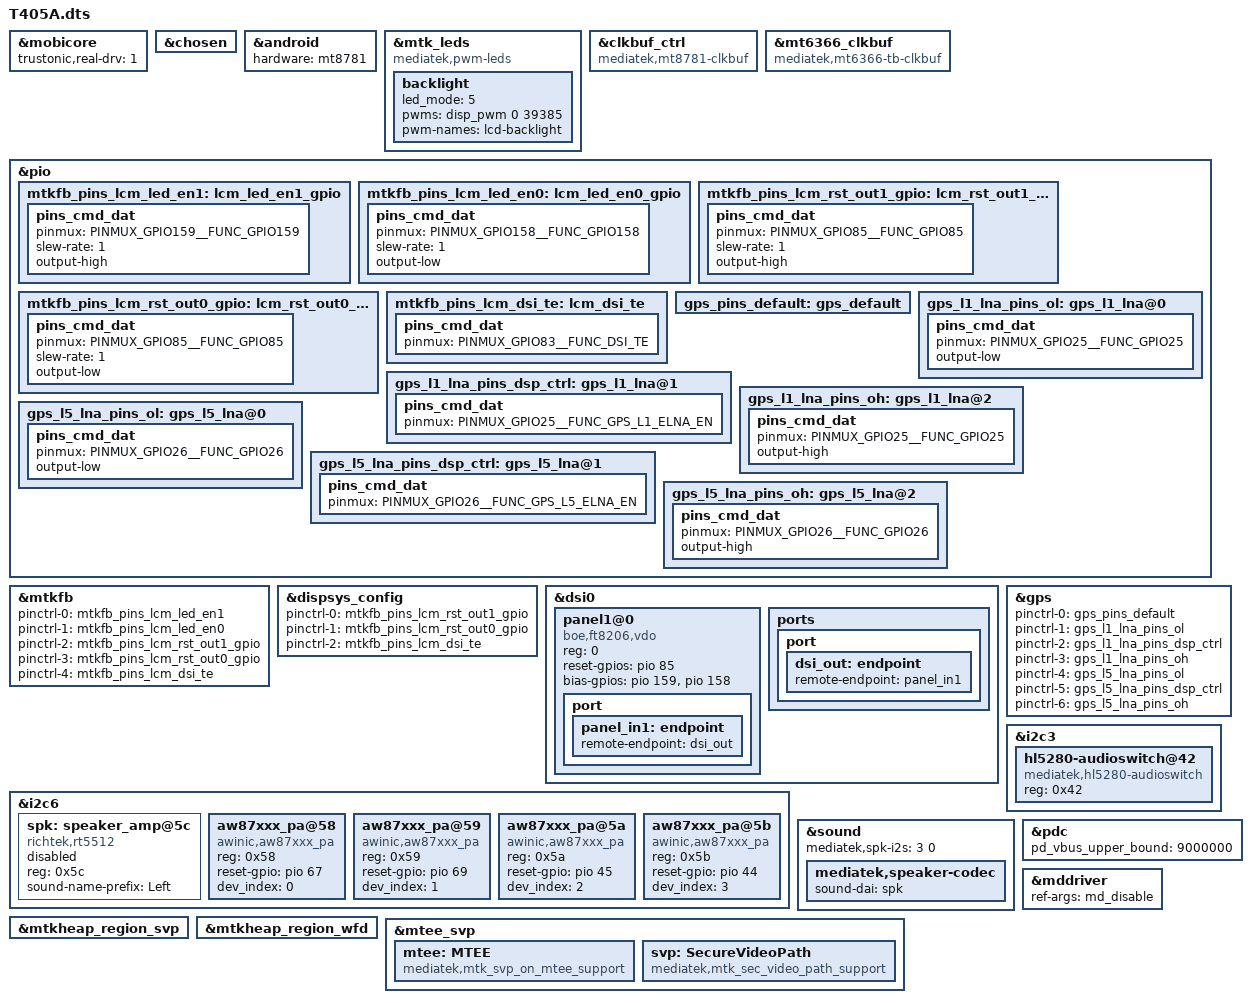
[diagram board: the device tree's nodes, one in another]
// SPDX-License-Identifier: (GPL-2.0 OR MIT)
/*
 * Copyright (C) 2021 MediaTek Inc.
 */
/dts-v1/;
/plugin/;
#include <dt-bindings/interrupt-controller/arm-gic.h>
#include <dt-bindings/interrupt-controller/irq.h>
#include <dt-bindings/pinctrl/mt6789-pinfunc.h>
#include "mediatek/cust_mt6789_camera_t405a.dtsi"
#include "mediatek/tinno_oem_charge.dtsi"

/* Trustonic Mobilecore real driver */
&mobicore{
	trustonic,real-drv = <1>;
};

&chosen {

};

&android {
	hardware = "mt8781";
};

&mtk_leds {
	compatible = "mediatek,pwm-leds";

	backlight {
		led_mode = <5>;
		pwms = <&disp_pwm 0 39385>;
		pwm-names = "lcd-backlight";
	};
};

&clkbuf_ctrl {
	compatible = "mediatek,mt8781-clkbuf";
};

&mt6366_clkbuf {
	compatible = "mediatek,mt6366-tb-clkbuf";
};

&pio {
	mtkfb_pins_lcm_led_en1: lcm_led_en1_gpio {
		pins_cmd_dat {
			pinmux = <PINMUX_GPIO159__FUNC_GPIO159>;
			slew-rate = <1>;
			output-high;
		};
	};

	mtkfb_pins_lcm_led_en0: lcm_led_en0_gpio {
		pins_cmd_dat {
			pinmux = <PINMUX_GPIO158__FUNC_GPIO158>;
			slew-rate = <1>;
			output-low;
		};
	};

	mtkfb_pins_lcm_rst_out1_gpio: lcm_rst_out1_gpio {
		pins_cmd_dat {
			pinmux = <PINMUX_GPIO85__FUNC_GPIO85>;
			slew-rate = <1>;
			output-high;
		};
	};

	mtkfb_pins_lcm_rst_out0_gpio: lcm_rst_out0_gpio {
		pins_cmd_dat {
			pinmux = <PINMUX_GPIO85__FUNC_GPIO85>;
			slew-rate = <1>;
			output-low;
		};
	};
	mtkfb_pins_lcm_dsi_te: lcm_dsi_te {
		pins_cmd_dat {
			pinmux = <PINMUX_GPIO83__FUNC_DSI_TE>;
		};
	};
};

&mtkfb {
	pinctrl-names = "lcm_led_en1_gpio", "lcm_led_en0_gpio",
		"lcm_rst_out1_gpio", "lcm_rst_out0_gpio",
		"mode_te_te";
	pinctrl-0 = <&mtkfb_pins_lcm_led_en1>;
	pinctrl-1 = <&mtkfb_pins_lcm_led_en0>;
	pinctrl-2 = <&mtkfb_pins_lcm_rst_out1_gpio>;
	pinctrl-3 = <&mtkfb_pins_lcm_rst_out0_gpio>;
	pinctrl-4 = <&mtkfb_pins_lcm_dsi_te>;
	status = "okay";
};

&dispsys_config {
	pinctrl-names =
		"lcm_rst_out1_gpio", "lcm_rst_out0_gpio",
		"mode_te_te";
	pinctrl-0 = <&mtkfb_pins_lcm_rst_out1_gpio>;
	pinctrl-1 = <&mtkfb_pins_lcm_rst_out0_gpio>;
	pinctrl-2 = <&mtkfb_pins_lcm_dsi_te>;
	status = "okay";
};

&dsi0 {
	status = "okay";
	#address-cells = <1>;
	#size-cells = <0>;
	panel1@0 {
		compatible = "boe,ft8206,vdo";
		reg = <0>;
		reset-gpios = <&pio 85 0>;
		bias-gpios = <&pio 159 0>,
			<&pio 158 0>;
		pinctrl-names = "default";
		port {
			panel_in1: endpoint {
				remote-endpoint = <&dsi_out>;
			};
		};
	};
	ports {
		port {
			dsi_out: endpoint {
				remote-endpoint = <&panel_in1>;
			};
		};
	};
};

/* GPS GPIO standardization start */
&pio {
	gps_pins_default: gps_default {
	};
	gps_l1_lna_pins_ol: gps_l1_lna@0 {
		pins_cmd_dat {
			pinmux = <PINMUX_GPIO25__FUNC_GPIO25>;
			output-low;
		};
	};
	gps_l1_lna_pins_dsp_ctrl: gps_l1_lna@1 {
		pins_cmd_dat {
			pinmux = <PINMUX_GPIO25__FUNC_GPS_L1_ELNA_EN>;
		};
	};
	gps_l1_lna_pins_oh: gps_l1_lna@2 {
		pins_cmd_dat {
			pinmux = <PINMUX_GPIO25__FUNC_GPIO25>;
			output-high;
		};
	};
	gps_l5_lna_pins_ol: gps_l5_lna@0 {
		pins_cmd_dat {
			pinmux = <PINMUX_GPIO26__FUNC_GPIO26>;
			output-low;
		};
	};
	gps_l5_lna_pins_dsp_ctrl: gps_l5_lna@1 {
		pins_cmd_dat {
			pinmux = <PINMUX_GPIO26__FUNC_GPS_L5_ELNA_EN>;
		};
	};
	gps_l5_lna_pins_oh: gps_l5_lna@2 {
		pins_cmd_dat {
			pinmux = <PINMUX_GPIO26__FUNC_GPIO26>;
			output-high;
		};
	};
};
&gps {
	pinctrl-names = "default",
		"gps_l1_lna_disable",
		"gps_l1_lna_dsp_ctrl",
		"gps_l1_lna_enable",
		"gps_l5_lna_disable",
		"gps_l5_lna_dsp_ctrl",
		"gps_l5_lna_enable";
	pinctrl-0 = <&gps_pins_default>;
	pinctrl-1 = <&gps_l1_lna_pins_ol>;
	pinctrl-2 = <&gps_l1_lna_pins_dsp_ctrl>;
	pinctrl-3 = <&gps_l1_lna_pins_oh>;
	pinctrl-4 = <&gps_l5_lna_pins_ol>;
	pinctrl-5 = <&gps_l5_lna_pins_dsp_ctrl>;
	pinctrl-6 = <&gps_l5_lna_pins_oh>;
	status = "okay";
};
/* GPS GPIO standardization end */

#include "mediatek/cust_mt6789_touch_1280x1840.dtsi"
#include "mediatek/cust_mt6789_camera_v4l2.dtsi"

&i2c6 {
	spk: speaker_amp@5c {
		compatible = "richtek,rt5512";
		#sound-dai-cells = <0>;
		reg = <0x5c>;
		status = "disabled";
		sound-name-prefix = "Left";
	};

        aw87xxx_pa@58 {
                compatible = "awinic,aw87xxx_pa","ocs,oca72xxx_pa";
                reg = <0x58>;
                reset-gpio = <&pio 67 0>;
                dev_index = < 0 >;
                status = "okay";
        };

        aw87xxx_pa@59 {
                compatible = "awinic,aw87xxx_pa","ocs,oca72xxx_pa";
                reg = <0x59>;
                reset-gpio = <&pio 69 0>;
                dev_index = < 1 >;
                status = "okay";
        };

        aw87xxx_pa@5a {
                compatible = "awinic,aw87xxx_pa","ocs,oca72xxx_pa";
                reg = <0x5a>;
                reset-gpio = <&pio 45 0>;
                dev_index = < 2 >;
                status = "okay";
        };

        aw87xxx_pa@5b {
                compatible = "awinic,aw87xxx_pa","ocs,oca72xxx_pa";
                reg = <0x5b>;
                reset-gpio = <&pio 44 0>;
                dev_index = < 3 >;
                status = "okay";
        };
};

&i2c3 {
        hl5280-audioswitch@42 {
                compatible = "mediatek,hl5280-audioswitch";
                reg = <0x42>;
                status = "okay";
        };
};

&sound {
	mediatek,spk-i2s = <3 0>;
	mediatek,speaker-codec {
		sound-dai = <&spk>;
	};
};

&pdc {
	pd_vbus_upper_bound = <9000000>;
};

&mddriver {
	ref-args = "md_disable";
};

&mtkheap_region_svp {
	status = "ok";
};

&mtkheap_region_wfd {
	status = "ok";
};

&mtee_svp {
	mtee: MTEE {
		compatible = "mediatek,mtk_svp_on_mtee_support";
	};

	svp: SecureVideoPath {
		compatible = "mediatek,mtk_sec_video_path_support";
	};
};

#include <T405A/cust.dtsi>
/*End of this file, DO NOT ADD ANYTHING HERE*/
